# FM33LG0XX register map
File version: 1.0
CPU: SC123 r1p0, little endian, no MPU, no FPU, 3 interrupt priority bits
Registers are 32-bit, read-write, reset 0x0 unless marked. A register's access mark holds for its fields unless they carry their own. Offsets are from the block's base; [hi:lo] are bit positions; {n}, {i} and the like mark numbered series.

## RTCA — RTCA module information
Base 0x40011000
0x00 WER — RTC Write Enable Register
  [0] WE — WE field description
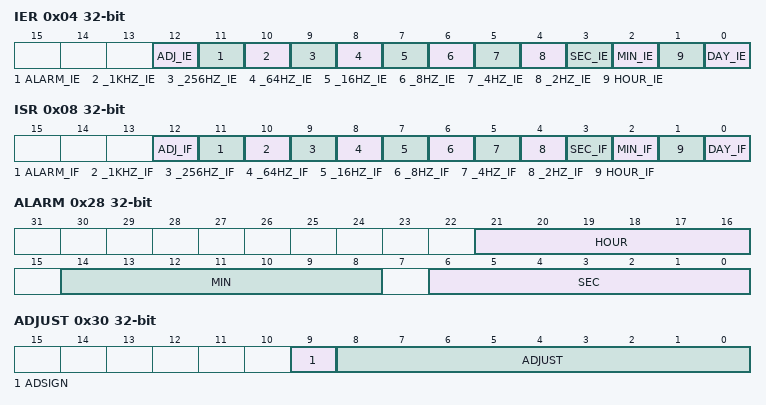
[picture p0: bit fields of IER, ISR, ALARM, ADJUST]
0x04 IER — RTC Interrupt Enable Register
  [12] ADJ_IE — ADJ_IE field description
  [11] ALARM_IE — ALARM_IE field description
  [10] _1KHZ_IE — _1KHZ_IE field description
  [9] _256HZ_IE — _256HZ_IE field description
  [8] _64HZ_IE — _64HZ_IE field description
  [7] _16HZ_IE — _16HZ_IE field description
  [6] _8HZ_IE — _8HZ_IE field description
  [5] _4HZ_IE — _4HZ_IE field description
  [4] _2HZ_IE — _2HZ_IE field description
  [3] SEC_IE — SEC_IE field description
  [2] MIN_IE — MIN_IE field description
  [1] HOUR_IE — HOUR_IE field description
  [0] DAY_IE — DAY_IE field description
0x08 ISR — RTC Interrupt Status Register
  [12] ADJ_IF — ADJ_IF field description
  [11] ALARM_IF — ALARM_IF field description
  [10] _1KHZ_IF — _1KHZ_IF field description
  [9] _256HZ_IF — _256HZ_IF field description
  [8] _64HZ_IF — _64HZ_IF field description
  [7] _16HZ_IF — _16HZ_IF field description
  [6] _8HZ_IF — _8HZ_IF field description
  [5] _4HZ_IF — _4HZ_IF field description
  [4] _2HZ_IF — _2HZ_IF field description
  [3] SEC_IF — SEC_IF field description
  [2] MIN_IF — MIN_IF field description
  [1] HOUR_IF — HOUR_IF field description
  [0] DAY_IF — DAY_IF field description
0x0C BCDSEC — BCD format time second registers
  [6:0] SEC — SEC field description
0x10 BCDMIN — BCD format time minute registers
  [6:0] MIN — MIN field description
0x14 BCDHOUR — BCD format time hour registers
  [5:0] HOUR — HOUR field description
0x18 BCDDAY — BCD format time day registers
  [5:0] DAY — DAY field description
0x1C BCDWEEK — BCD format time week registers
  [2:0] WEEK — WEEK field description
0x20 BCDMONTH — BCD format time month registers
  [4:0] MONTH — MONTH field description
0x24 BCDYEAR — BCD format time year registers
  [7:0] YEAR — YEAR field description
0x28 ALARM — RTCA Alarm Register
  [21:16] HOUR — HOUR field description
  [14:8] MIN — MIN field description
  [6:0] SEC — SEC field description
0x2C TMSEL — RTCA Time Mark Select
  [3:0] TMSEL — TMSEL field description
0x30 ADJUST — RTCA time Adjust Register
  [9] ADSIGN — ADSIGN field description
  [8:0] ADJUST — ADJUST field description
0x3C SBSCNT — RTCA Sub-Second Counter
  [7:0] MSCNT — MSCNT field description
0x7C CR — RTCA Control Register
  [0] EN — EN field description

## RTCB — RTCB module information
Base 0x4001F000
0x00 WER — RTCBWrite Enable Register
  [0] WE — WE field description
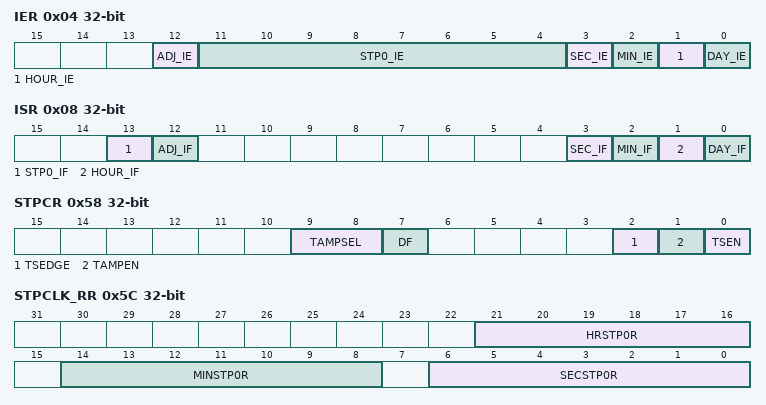
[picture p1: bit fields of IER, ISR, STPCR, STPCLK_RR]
0x04 IER — RTCBInterrupt Enable Register
  [12] ADJ_IE — ADJ_IE field description
  [11:4] STP0_IE — STP0_IE field description
  [3] SEC_IE — SEC_IE field description
  [2] MIN_IE — MIN_IE field description
  [1] HOUR_IE — HOUR_IE field description
  [0] DAY_IE — DAY_IE field description
0x08 ISR — RTCBInterrupt Status Register
  [13] STP0_IF — STP0_IF field description
  [12] ADJ_IF — ADJ_IF field description
  [3] SEC_IF — SEC_IF field description
  [2] MIN_IF — MIN_IF field description
  [1] HOUR_IF — HOUR_IF field description
  [0] DAY_IF — DAY_IF field description
0x0C BCDSEC — BCD format time second registers
  [6:0] SEC — SEC field description
0x10 BCDMIN — BCD format time minute registers
  [6:0] MIN — MIN field description
0x14 BCDHOUR — BCD format time hour registers
  [5:0] HOUR — HOUR field description
0x18 BCDDAY — BCD format time day registers
  [5:0] DAY — DAY field description
0x1C BCDWEEK — BCD format time week registers
  [2:0] WEEK — WEEK field description
0x20 BCDMONTH — BCD format time month registers
  [4:0] MONTH — MONTH field description
0x24 BCDYEAR — BCD format time year registers
  [7:0] YEAR — YEAR field description
0x2C TMSEL — RTCB Time Mark Select
  [3:0] TMSEL — TMSEL field description
0x30 ADJR — RTCB time Adjust Register
  [9:0] ADJUST — ADJUST field description
0x50 CR reset 0x1 — RTCB Control Register
  [0] EN — EN field description
0x58 STPCR — RTCB Time Stamp Control Register
  [9:8] TAMPSEL — TAMPSEL field description
  [7] DF — DF field description
  [2] TSEDGE — TSEDGE field description
  [1] TAMPEN — TAMPEN field description
  [0] TSEN — TSEN field description
0x5C STPCLK_RR — RTC Time Stamp Clock Record Register
  [21:16] HRSTP0R — HRSTP0R field description
  [14:8] MINSTP0R — MINSTP0R field description
  [6:0] SECSTP0R — SECSTP0R field description
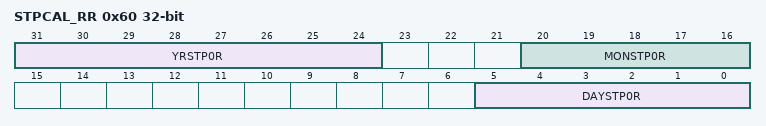
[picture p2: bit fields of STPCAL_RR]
0x60 STPCAL_RR — RTCB Time Stamp Calendar Record Register
  [31:24] YRSTP0R — YRSTP0R field description
  [20:16] MONSTP0R — MONSTP0R field description
  [5:0] DAYSTP0R — DAYSTP0R field description
0x6C BKR0 — RTCBBackup Register0
  [31:0] BKP — BKP field description
{0x6C+4i} BKR{i} (i=1..4) — RTCB Backup Register{i}
  [31:0] BKP — BKP field description
